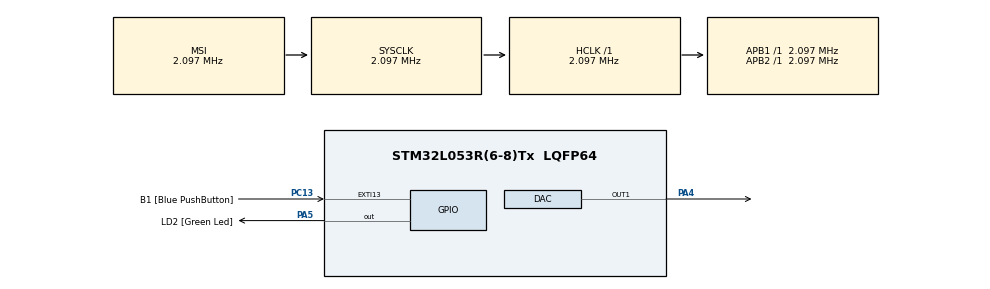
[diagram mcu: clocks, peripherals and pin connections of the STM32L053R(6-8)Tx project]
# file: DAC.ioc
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Mcu.Family=STM32L0
Mcu.Name=STM32L053R(6-8)Tx
Mcu.Package=LQFP64
PA13.GPIO_Label=TMS
PA13.Signal=SYS_SWDIO
PA14.GPIO_Label=TCK
PA14.Signal=SYS_SWCLK
PA2.GPIO_Label=USART_TX
PA2.Signal=USART2_TX
PA3.GPIO_Label=USART_RX
PA3.Signal=USART2_RX
PA4.Signal=COMP_DAC1_group
PA5.GPIO_Label=LD2 [Green Led]
PA5.Signal=GPIO_Output
PC13.GPIO_Label=B1 [Blue PushButton]
PC13.GPIO_ModeDefaultEXTI=GPIO_MODE_IT_FALLING
PC13.Signal=GPXTI13
PC14-OSC32_IN.Signal=RCC_OSC32_IN
PC15-OSC32_OUT.Signal=RCC_OSC32_OUT
PH0-OSC_IN.Signal=RCC_OSC_IN
PH1-OSC_OUT.Signal=RCC_OSC_OUT
ProjectManager.HeapSize=0x200
ProjectManager.StackSize=0x400
ProjectManager.TargetToolchain=STM32CubeIDE
RCC.AHBFreq_Value=2097000
RCC.APB1Freq_Value=2097000
RCC.APB1TimFreq_Value=2097000
RCC.APB2Freq_Value=2097000
RCC.APB2TimFreq_Value=2097000
RCC.HSE_VALUE=8000000
RCC.HSI16_VALUE=16000000
RCC.HSI48_VALUE=48000000
RCC.HSI_VALUE=16000000
RCC.LSEState=RCC_LSE_ON
RCC.LSE_VALUE=32768
RCC.MSI_VALUE=2097000
RCC.SYSCLKFreq_VALUE=2097000
RCC.VCOOutputFreq_Value=48000000
SH.COMP_DAC1_group.0=DAC_OUT1,DAC_OUT1
board=NUCLEO-L053R8

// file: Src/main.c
/* USER CODE BEGIN Header */
/**
  ******************************************************************************
  * @file           : main.c
  * @brief          : Main program body
  ******************************************************************************
  * @attention
  *
  * <h2><center>&copy; Copyright (c) 2020 STMicroelectronics.
  * All rights reserved.</center></h2>
  *
  * This software component is licensed by ST under BSD 3-Clause license,
  * the "License"; You may not use this file except in compliance with the
  * License. You may obtain a copy of the License at:
  *                        opensource.org/licenses/BSD-3-Clause
  *
  ******************************************************************************
  */
/* USER CODE END Header */

#include "main.h"

DAC_HandleTypeDef hdac;

void SystemClock_Config(void);
static void MX_GPIO_Init(void);
static void MX_DAC_Init(void);

int main(void)
{

  /* MCU Configuration--------------------------------------------------------*/

  /* Reset of all peripherals, Initializes the Flash interface and the Systick. */
  HAL_Init();

  /* Configure the system clock */
  SystemClock_Config();

  /* Initialize all configured peripherals */
  MX_GPIO_Init();
  MX_DAC_Init();
  /* USER CODE BEGIN 2 */
  int i;
  /* USER CODE END 2 */

  /* Infinite loop */
  /* USER CODE BEGIN WHILE */
  while (1)
  {
	  HAL_DAC_Start(&hdac, DAC_CHANNEL_1);
	  HAL_DAC_SetValue(&hdac, DAC_CHANNEL_1, DAC_ALIGN_12B_R, i);
	  HAL_DAC_Stop(&hdac, DAC_CHANNEL_1);
	  i = i == 4096 ? 0: i+1;
    /* USER CODE END WHILE */

  }
}

void SystemClock_Config(void)
{
  RCC_OscInitTypeDef RCC_OscInitStruct = {0};
  RCC_ClkInitTypeDef RCC_ClkInitStruct = {0};

  /** Configure the main internal regulator output voltage
  */
  __HAL_PWR_VOLTAGESCALING_CONFIG(PWR_REGULATOR_VOLTAGE_SCALE1);
  /** Initializes the CPU, AHB and APB busses clocks
  */
  RCC_OscInitStruct.OscillatorType = RCC_OSCILLATORTYPE_MSI;
  RCC_OscInitStruct.MSIState = RCC_MSI_ON;
  RCC_OscInitStruct.MSICalibrationValue = 0;
  RCC_OscInitStruct.MSIClockRange = RCC_MSIRANGE_5;
  RCC_OscInitStruct.PLL.PLLState = RCC_PLL_NONE;
  if (HAL_RCC_OscConfig(&RCC_OscInitStruct) != HAL_OK)
  {
    Error_Handler();
  }
  /** Initializes the CPU, AHB and APB busses clocks
  */
  RCC_ClkInitStruct.ClockType = RCC_CLOCKTYPE_HCLK|RCC_CLOCKTYPE_SYSCLK
                              |RCC_CLOCKTYPE_PCLK1|RCC_CLOCKTYPE_PCLK2;
  RCC_ClkInitStruct.SYSCLKSource = RCC_SYSCLKSOURCE_MSI;
  RCC_ClkInitStruct.AHBCLKDivider = RCC_SYSCLK_DIV1;
  RCC_ClkInitStruct.APB1CLKDivider = RCC_HCLK_DIV1;
  RCC_ClkInitStruct.APB2CLKDivider = RCC_HCLK_DIV1;

  if (HAL_RCC_ClockConfig(&RCC_ClkInitStruct, FLASH_LATENCY_0) != HAL_OK)
  {
    Error_Handler();
  }
}

static void MX_DAC_Init(void)
{

  DAC_ChannelConfTypeDef sConfig = {0};

  /** DAC Initialization
  */
  hdac.Instance = DAC;
  if (HAL_DAC_Init(&hdac) != HAL_OK)
  {
    Error_Handler();
  }
  /** DAC channel OUT1 config
  */
  sConfig.DAC_Trigger = DAC_TRIGGER_NONE;
  sConfig.DAC_OutputBuffer = DAC_OUTPUTBUFFER_ENABLE;
  if (HAL_DAC_ConfigChannel(&hdac, &sConfig, DAC_CHANNEL_1) != HAL_OK)
  {
    Error_Handler();
  }

}

static void MX_GPIO_Init(void)
{
  GPIO_InitTypeDef GPIO_InitStruct = {0};

  /* GPIO Ports Clock Enable */
  __HAL_RCC_GPIOC_CLK_ENABLE();
  __HAL_RCC_GPIOH_CLK_ENABLE();
  __HAL_RCC_GPIOA_CLK_ENABLE();

  /*Configure GPIO pin Output Level */
  HAL_GPIO_WritePin(LD2_GPIO_Port, LD2_Pin, GPIO_PIN_RESET);

  /*Configure GPIO pin : B1_Pin */
  GPIO_InitStruct.Pin = B1_Pin;
  GPIO_InitStruct.Mode = GPIO_MODE_IT_FALLING;
  GPIO_InitStruct.Pull = GPIO_NOPULL;
  HAL_GPIO_Init(B1_GPIO_Port, &GPIO_InitStruct);

  /*Configure GPIO pins : USART_TX_Pin USART_RX_Pin */
  GPIO_InitStruct.Pin = USART_TX_Pin|USART_RX_Pin;
  GPIO_InitStruct.Mode = GPIO_MODE_AF_PP;
  GPIO_InitStruct.Pull = GPIO_NOPULL;
  GPIO_InitStruct.Speed = GPIO_SPEED_FREQ_VERY_HIGH;
  GPIO_InitStruct.Alternate = GPIO_AF4_USART2;
  HAL_GPIO_Init(GPIOA, &GPIO_InitStruct);

  /*Configure GPIO pin : LD2_Pin */
  GPIO_InitStruct.Pin = LD2_Pin;
  GPIO_InitStruct.Mode = GPIO_MODE_OUTPUT_PP;
  GPIO_InitStruct.Pull = GPIO_NOPULL;
  GPIO_InitStruct.Speed = GPIO_SPEED_FREQ_LOW;
  HAL_GPIO_Init(LD2_GPIO_Port, &GPIO_InitStruct);

}

void Error_Handler(void)
{
}

/************************ (C) COPYRIGHT STMicroelectronics *****END OF FILE****/
